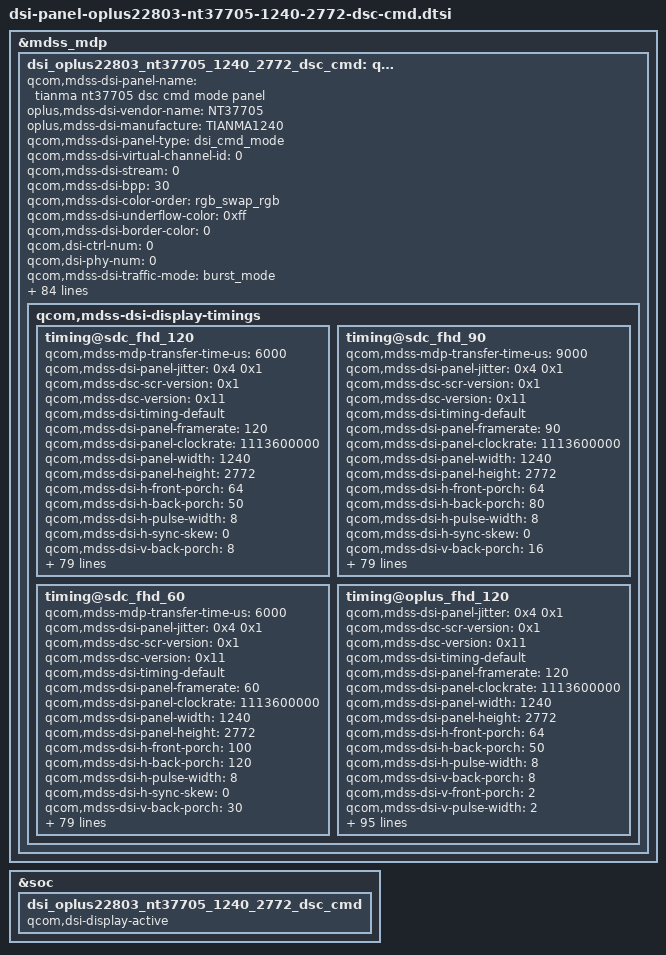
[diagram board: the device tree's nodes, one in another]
&mdss_mdp {
	dsi_oplus22803_nt37705_1240_2772_dsc_cmd: qcom,mdss_dsi_oplus22803_nt37705_1240_2772_dsc_cmd {
		qcom,mdss-dsi-panel-name = "tianma nt37705 dsc cmd mode panel";
		oplus,mdss-dsi-vendor-name = "NT37705";
		oplus,mdss-dsi-manufacture = "TIANMA1240";
		qcom,mdss-dsi-panel-type = "dsi_cmd_mode";
		qcom,mdss-dsi-virtual-channel-id = <0>;
		qcom,mdss-dsi-stream = <0>;
		qcom,mdss-dsi-bpp = <30>;
		qcom,mdss-dsi-color-order = "rgb_swap_rgb";
		qcom,mdss-dsi-underflow-color = <0xff>;
		qcom,mdss-dsi-border-color = <0>;
		qcom,dsi-ctrl-num = <0>;
		qcom,dsi-phy-num = <0>;
		qcom,mdss-dsi-traffic-mode = "burst_mode";
		qcom,mdss-dsi-lane-map = "lane_map_0123";
		qcom,mdss-dsi-bllp-eof-power-mode;
		qcom,mdss-dsi-bllp-power-mode;
		qcom,mdss-dsi-lane-0-state;
		qcom,mdss-dsi-lane-1-state;
		qcom,mdss-dsi-lane-2-state;
		qcom,mdss-dsi-lane-3-state;
		qcom,mdss-dsi-dma-trigger = "trigger_sw";
		qcom,mdss-loading-effect;
		qcom,mdss-dsi-mdp-trigger = "none";
		qcom,mdss-dsi-reset-sequence = <1 2>, <0 5>, <1 10>;
		qcom,mdss-dsi-te-pin-select = <1>;
		qcom,mdss-dsi-te-dcs-command = <1>;
		qcom,mdss-pan-physical-width-dimension = <70>;
		qcom,mdss-pan-physical-height-dimension = <155>;
		qcom,mdss-dsi-init-delay-us = <1000>;
		qcom,mdss-dsi-te-check-enable;
		qcom,mdss-dsi-te-using-te-pin;
		qcom,mdss-dsi-lp11-init;
		qcom,mdss-dsi-wr-mem-start = <0x2c>;
		qcom,mdss-dsi-wr-mem-continue = <0x3c>;
		qcom,mdss-dsi-panel-jitter = <0x4 0x1>;
		qcom,mdss-dsc-scr-version = <0x1>;
		qcom,mdss-bl-high2bit;
		/* HDR Setting */
		qcom,mdss-dsi-panel-hdr-enabled;
		qcom,mdss-dsi-panel-hdr-color-primaries = <15635 16450 34000 16000 13250 34500 7500 3000>;
		qcom,mdss-dsi-panel-peak-brightness = <5400000>;
		qcom,mdss-dsi-panel-average-brightness = <2000000>;
		qcom,mdss-dsi-panel-blackness-level = <4000>;

		qcom,esd-check-enabled;
		//oplus,esd-check-flag-enabled;
		qcom,mdss-dsi-panel-status-check-mode = "reg_read";
		qcom,mdss-dsi-panel-status-command = [
				06 01 00 01 05 00 02 0A 00
			];
		qcom,mdss-dsi-panel-status-command-state = "dsi_lp_mode";
		qcom,mdss-dsi-panel-status-value = <0x9C>;
		qcom,mdss-dsi-panel-status-read-length = <1>;

		qcom,dynamic-mode-switch-enabled;
		qcom,dynamic-mode-switch-type = "dynamic-resolution-switch-immediate";
		qcom,mdss-dsi-display-timings {
			timing@sdc_fhd_120{
				qcom,mdss-mdp-transfer-time-us = <6000>;
				qcom,mdss-dsi-panel-jitter = <0x4 0x1>;
				qcom,mdss-dsc-scr-version = <0x1>;
				qcom,mdss-dsc-version = <0x11>;
				qcom,mdss-dsi-timing-default;
				qcom,mdss-dsi-panel-framerate = <120>;
				qcom,mdss-dsi-panel-clockrate = <1113600000>;
				qcom,mdss-dsi-panel-width = <1240>;
				qcom,mdss-dsi-panel-height = <2772>;

				qcom,mdss-dsi-h-front-porch = <64>;
				qcom,mdss-dsi-h-back-porch = <50>;
				qcom,mdss-dsi-h-pulse-width = <8>;
				qcom,mdss-dsi-h-sync-skew = <0>;
				qcom,mdss-dsi-v-back-porch = <8>;
				qcom,mdss-dsi-v-front-porch = <2>;
				qcom,mdss-dsi-v-pulse-width = <2>;
				qcom,mdss-dsi-h-sync-pulse = <0>;

				qcom,mdss-dsi-h-left-border = <0>;
				qcom,mdss-dsi-h-right-border = <0>;
				qcom,mdss-dsi-v-top-border = <0>;
				qcom,mdss-dsi-v-bottom-border = <0>;

				/* Apollo vsync config, need to measure TE signal */
				//oplus,apollo-panel-vsync-width = <13000>;
				//oplus,apollo-panel-vsync-period = <16600>;

				oplus,fod-on-vblank = <0>;
				oplus,fod-off-vblank = <0>;
				qcom,mdss-dsi-panel-read-register-open-command = [
					39 01 00 00 00 00 03 F0 5A 5A
					];
				qcom,mdss-dsi-panel-id1-command = [
					06 01 00 00 00 00 01 E9
					];
				qcom,mdss-dsi-panel-read-register-close-command = [
					39 01 00 00 00 00 03 F0 A5 A5
					];
				qcom,mdss-dsi-timing-switch-command = [
					/* Frequence Transition */
					39 00 00 00 11 00 02 2F 00
					/* TE change */
					39 00 00 40 00 00 06 F0 55 AA 52 08 00
					39 00 00 00 00 00 02 BE 47

					39 00 00 40 00 00 06 F0 55 AA 52 08 00
					39 00 00 40 00 00 02 6F A8
					39 00 00 40 00 00 03 BA 00 00
					39 00 00 40 00 00 02 6F B0
					39 00 00 40 00 00 05 BA 00 00 00 00
					39 00 00 40 00 00 02 2F 30
					39 00 00 40 00 00 02 6D 00
					39 00 00 40 00 00 05 35 00 00 00 00
					39 00 00 00 00 00 03 44 00 00
					];
				qcom,mdss-dsi-on-command=[
					39 00 00 40 00 00 06 F0 55 AA 52 08 01
					39 00 00 40 00 00 02 6F 0C
					39 00 00 00 00 00 03 B5 80 E6
					39 00 00 40 00 00 05 FF AA 55 A5 81
					39 00 00 40 00 00 02 6F 19
					39 00 00 40 00 00 02 FB 00
					39 00 00 40 00 00 02 6F 05
					39 00 00 40 00 00 02 FE 34
					39 00 00 40 00 00 05 FF AA 55 A5 80
					39 00 00 40 00 00 02 6F 1A
					39 00 00 40 00 00 02 F4 55
					39 00 00 40 00 00 05 FF AA 55 A5 83
					39 00 00 40 00 00 02 6F 12
					39 00 00 40 00 00 02 FE 41
					39 00 00 40 00 00 02 5F 00
					39 00 00 40 00 00 02 26 00
					39 00 00 40 00 00 02 26 00
					39 00 00 40 00 00 02 17 10
					39 00 00 40 00 00 05 2A 00 00 04 D7
					39 00 00 00 00 00 05 2B 00 00 0A D3
					/*TE 120hz*/
					39 00 00 00 00 00 02 2F 00
					/*TE on*/
					39 00 00 40 00 00 02 35 00
					39 00 00 40 00 00 03 44 00 00
					/* Dimming Setting */
					39 00 00 40 00 00 03 51 0D BB
					39 00 00 00 00 00 02 6F 04
					39 00 00 40 00 00 03 51 03 FF
					39 00 00 00 00 00 02 53 20
					/*10bit DSC*/
					39 00 00 40 00 00 03 90 03 03
					39 00 00 00 00 00 13 91 AB 28 00 0C F2 00 02 85 01 0F 00 08 0A E9 07 5F 10 F0
					39 00 00 40 00 00 05 FF AA 55 A5 81
					39 00 00 40 00 00 02 6F 24
					39 00 00 40 00 00 15 FB 00 03 04 55 77 77 77 99 9D 00 00 06 88 9A BB BC DE EF F0 11
					39 00 00 40 00 00 05 FF AA 55 A5 81
					39 00 00 40 00 00 02 6F 0E
					39 00 00 40 00 00 02 F5 00
					39 00 00 40 00 00 05 FF AA 55 A5 80
					39 00 00 40 00 00 02 6F 0F
					39 00 00 40 00 00 02 FC 00
					39 00 00 40 00 00 02 6F 09
					39 00 00 00 00 00 03 FC FC F0
					/*OSC start*/
					39 00 00 40 00 00 05 FF AA 55 A5 80
					39 00 00 40 00 00 02 6F 0A
					39 00 00 40 00 00 04 F6 70 70 70
					39 00 00 40 00 00 02 6F 0E
					39 00 00 40 00 00 02 F6 60
					39 00 00 40 00 00 05 FF AA 55 A5 80
					39 00 00 40 00 00 02 6F 11
					39 00 00 40 00 00 03 F8 01 50
					39 00 00 40 00 00 02 6F 2D
					39 00 00 40 00 00 03 F8 00 FC
					39 00 00 40 00 00 02 6F 01
					39 00 00 40 00 00 02 1F 06
					39 00 00 40 00 00 05 FF AA 55 A5 81
					39 00 00 40 00 00 02 6F 1E
					39 00 00 00 00 00 02 FB 0F
					/*OSC end*/
					39 00 00 40 00 00 05 FF AA 55 A5 83
					39 00 00 40 00 00 02 6F 12
					39 00 00 40 00 00 02 FE 41
					39 00 00 40 00 00 05 FF AA 55 A5 80
					39 00 00 40 00 00 02 6F 19
					39 00 00 40 00 00 02 F2 00
					39 00 00 40 00 00 05 FF AA 55 A5 81
					39 00 00 40 00 00 02 6F 02
					39 00 00 40 00 00 02 F9 04
					39 00 00 00 00 00 02 5A 00
					39 00 00 40 00 00 06 F0 55 AA 52 08 01
					39 00 00 00 00 00 05 E9 58 08 08 28
					/* Switch to 120Hz */
					39 00 00 40 00 00 06 F0 55 AA 52 08 00
					39 00 00 40 00 00 02 6F A8
					39 00 00 40 00 00 03 BA 00 00
					39 00 00 40 00 00 02 6F B0
					39 00 00 40 00 00 05 BA 00 00 00 00
					39 00 00 40 00 00 02 2F 30
					39 00 00 40 00 00 02 6D 00
					39 00 00 40 00 00 05 35 00 00 00 00
					/* Edge Optimization Control */
					39 00 00 40 00 00 06 F0 55 AA 52 08 07
					39 00 00 00 00 00 0E B4 C0 80 80 80 80 50 80 80 80 80 80 50 80
					/* SPR Control */
					39 00 00 40 00 00 06 F0 55 AA 52 08 07
					39 00 00 00 00 00 07 B1 08 18 00 18 08 00
					/* R Corner Control */
					39 00 00 40 00 00 06 F0 55 AA 52 08 07
					39 00 00 40 00 00 04 C0 87 01 08
					39 00 00 40 00 00 02 6F 03
					39 00 00 40 00 00 0F C0 00 00 00 55 00 00 00 00 00 00 00 00 00 00
					39 00 00 40 00 00 02 6F 00
					39 00 00 40 00 00 16 C1 38 0F 0B 64 01 21 F8 D4 3F FC 8B 78 3F FF 19 B4 80 00 2E C8 91
					39 00 00 40 00 00 02 6F 15
					39 00 00 40 00 00 11 C1 66 00 00 11 00 39 A0 43 F0 9A EF 06 C6 C0 00 FF
					39 00 00 40 00 00 02 6F 25
					39 00 00 00 00 00 11 C1 00 2F 3A 00 07 0F 00 00 00 66 40 40 40 40 40 40
					39 00 00 40 00 00 02 6F 00
					39 00 00 40 00 00 16 C2 30 0F 01 00 05 10 FB 80 3F FF 48 00 3F FD 9E 00 00 00 21 C9 00
					39 00 00 40 00 00 02 6F 15
					39 00 00 40 00 00 11 C2 10 00 3B 98 00 00 10 34 F0 F0 A4 05 C0 30 FF 00
					39 00 00 40 00 00 02 6F 25
					39 00 00 00 00 00 11 C2 00 00 10 00 26 38 00 00 00 10 40 40 40 40 40 40
					39 00 00 40 00 00 02 6F 00
					39 00 00 40 00 00 16 C3 30 0F 00 79 00 90 FE F8 3F FF 76 E0 3F FF 70 D0 80 00 13 91 11
					39 00 00 40 00 00 02 6F 15
					39 00 00 40 00 00 11 C3 11 00 11 3A 00 10 38 44 F0 D9 D8 06 18 F0 FF FF
					39 00 00 40 00 00 02 6F 25
					39 00 00 00 00 00 11 C3 44 9D A3 00 08 0F 00 00 00 11 40 40 40 40 40 40
					39 00 00 40 00 00 02 6F 00
					39 00 00 40 00 00 16 C4 32 0F 01 21 06 40 FA B0 00 00 5A 50 00 04 66 84 FF FF AE 22 FC
					39 00 00 40 00 00 02 6F 15
					39 00 00 40 00 00 11 C4 11 44 34 9B AA C2 D3 34 0F 11 66 F9 3A 00 00 00
					39 00 00 40 00 00 02 6F 25
					39 00 00 00 00 00 11 C4 44 C7 D4 00 2C 39 00 00 00 11 40 40 40 40 40 40
					39 00 00 40 00 00 02 6F 00
					39 00 00 40 00 00 16 C5 3A 0F 00 79 00 90 FE F8 00 00 8B 88 00 00 8C 90 FF FF E7 3E 80
					39 00 00 40 00 00 02 6F 15
					39 00 00 40 00 00 11 C5 0D 44 9C C5 AA 9A C2 54 0F 27 28 F9 E8 00 00 00
					39 00 00 40 00 00 02 6F 25
					39 00 00 00 00 00 11 C5 44 C5 CC AA 9A A4 00 00 00 0D 40 40 40 40 40 40
					39 00 00 40 00 00 02 6F 00
					39 00 00 40 00 00 16 C6 3A 0F 07 90 01 44 F9 D0 00 05 1D C8 00 00 6F 60 7F FF 9A 55 B0
					39 00 00 40 00 00 02 6F 15
					39 00 00 40 00 00 11 C6 6A 44 C5 D7 AA 2E 99 43 0F 6A 12 F8 8C 00 00 00
					39 00 00 40 00 00 02 6F 25
					39 00 00 00 00 00 11 C6 44 9C A6 AA C2 CB 00 00 00 6A 40 40 40 40 40 40
					39 00 00 40 00 00 02 6F 00
					39 00 00 40 00 00 16 C7 36 00 01 00 05 10 04 80 00 00 00 00 3F FC 00 00 00 00 00 00 00
					39 00 00 40 00 00 02 6F 15
					39 00 00 40 00 00 11 C7 10 44 3F 9C 00 00 10 34 30 10 A4 00 00 00 00 00
					39 00 00 40 00 00 02 6F 25
					39 00 00 00 00 00 11 C7 00 09 12 AA 9A A4 00 00 00 10 40 40 40 40 40 40
					39 00 00 40 00 00 02 6F 00
					39 00 00 40 00 00 16 C8 36 00 00 79 00 90 01 08 00 00 63 50 3F FF 47 90 80 00 00 B9 00
					39 00 00 40 00 00 02 6F 15
					39 00 00 40 00 00 11 C8 11 44 9D C6 00 10 38 44 30 27 D8 00 00 C0 00 FF
					39 00 00 40 00 00 02 6F 25
					39 00 00 00 00 00 11 C8 00 31 3B AA C2 CD 00 00 00 11 40 40 40 40 40 40
					39 00 00 40 00 00 02 6F 00
					39 00 00 40 00 00 16 C9 2E 00 0B 64 01 21 07 2C 00 01 F1 40 3F FE 9F C8 80 00 01 61 59
					39 00 00 40 00 00 02 6F 15
					39 00 00 40 00 00 11 C9 66 44 C6 D7 00 39 A0 43 30 66 EF 00 00 C0 00 FF
					39 00 00 40 00 00 02 6F 25
					39 00 00 00 00 00 11 C9 00 00 00 00 00 00 00 00 00 66 40 40 40 40 40 40
					39 00 00 40 00 00 02 6F 00
					39 00 00 40 00 00 16 CA 2C 00 07 90 01 44 06 30 3F F9 D1 F8 00 00 00 00 00 00 00 00 00
					39 00 00 40 00 00 02 6F 15
					39 00 00 40 00 00 11 CA 6A 00 00 12 AA 2E 99 43 C0 96 12 00 00 00 00 00
					39 00 00 40 00 00 02 6F 25
					39 00 00 00 00 00 11 CA 00 00 00 00 00 00 00 00 00 6A 40 40 40 40 40 40
					39 00 00 40 00 00 02 6F 00
					39 00 00 40 00 00 16 CB 2C 00 00 79 00 90 01 08 3F FF 4E A8 00 00 63 50 00 00 00 B1 D1
					39 00 00 40 00 00 02 6F 15
					39 00 00 40 00 00 11 CB 0D 00 12 3B AA 9A C2 54 C0 D9 28 00 00 30 FF 00
					39 00 00 40 00 00 02 6F 25
					39 00 00 00 00 00 11 CB 00 00 00 00 00 00 00 00 00 0D 40 40 40 40 40 40
					39 00 00 40 00 00 02 6F 00
					39 00 00 40 00 00 16 CC 24 00 01 21 06 40 05 50 3F FE BF 64 00 02 48 A4 80 00 01 41 BD
					39 00 00 40 00 00 02 6F 15
					39 00 00 40 00 00 11 CC 11 00 3C A3 AA C2 D3 34 C0 EF 66 00 00 30 FF 00
					39 00 00 40 00 00 02 6F 25
					39 00 00 00 00 00 11 CC 00 00 00 00 00 00 00 00 00 11 40 40 40 40 40 40
					39 00 00 40 00 00 02 6F 00
					39 00 00 40 00 00 16 D1 21 00 04 C9 04 C9 00 00 3F FE B1 0A 3F FE B1 0A 00 00 19 8D 4F
					39 00 00 40 00 00 02 6F 15
					39 00 00 40 00 00 11 D1 0A 22 47 6B 00 25 49 55 F0 DD DD 04 C9 F0 FF FF
					39 00 00 40 00 00 02 6F 25
					39 00 00 00 00 00 11 D1 00 00 00 00 00 00 00 00 00 0A 40 40 40 40 40 40
					39 00 00 40 00 00 02 6F 00
					39 00 00 40 00 00 16 D2 27 00 04 C9 04 C9 00 00 00 00 00 00 3F FE B1 0A 00 00 01 53 BF
					39 00 00 40 00 00 02 6F 15
					39 00 00 40 00 00 11 D2 0A 22 6C 90 00 25 49 55 30 23 DD 00 00 C0 00 FF
					39 00 00 40 00 00 02 6F 25
					39 00 00 00 00 00 11 D2 00 00 00 00 00 00 00 00 00 0A 40 40 40 40 40 40
					39 00 00 40 00 00 02 6F 00
					39 00 00 40 00 00 16 D3 2D 00 04 C9 05 10 00 00 3F FE A7 78 00 00 00 00 00 00 01 5D 51
					39 00 00 40 00 00 02 6F 15
					39 00 00 40 00 00 11 D3 18 22 47 6C 00 4A 6E 55 C0 DD 24 00 00 30 FF 00
					39 00 00 40 00 00 02 6F 25
					39 00 00 00 00 00 11 D3 00 00 00 00 00 00 00 00 00 18 40 40 40 40 40 40
					39 00 00 40 00 00 02 6F 00
					39 00 00 40 00 00 16 D4 2B 00 04 C9 04 84 00 00 00 00 00 00 00 00 00 00 7F FF EA 64 5C
					39 00 00 40 00 00 02 6F 15
					39 00 00 40 00 00 11 D4 19 22 6D 90 00 4A 6E 55 0F 23 22 FB 5A 00 00 00
					39 00 00 40 00 00 02 6F 25
					39 00 00 00 00 00 11 D4 00 00 00 00 00 00 00 00 00 19 40 40 40 40 40 40
					/* corsstalk improvements */
					39 00 00 40 00 00 06 F0 55 AA 52 08 08
					39 00 00 40 00 00 03 BF 11 11
					39 00 00 40 00 00 02 6F 01
					39 00 00 40 00 00 02 BF 00
					39 00 00 40 00 00 02 6F 02
					39 00 00 40 00 00 02 BF 08
					39 00 00 40 00 00 02 6F 03
					39 00 00 40 00 00 0A BF 00 20 3F 59 73 A0 C0 E0 F0
					39 00 00 40 00 00 02 6F 0C
					39 00 00 40 00 00 09 BF 08 08 10 08 08 08 08 08
					39 00 00 40 00 00 02 6F 14
					39 00 00 40 00 00 09 BF 08 08 10 08 08 08 08 08
					39 00 00 40 00 00 02 6F 1C
					39 00 00 40 00 00 09 BF 20 28 20 10 08 04 00 00
					39 00 00 40 00 00 02 6F 24
					39 00 00 40 00 00 09 BF 20 28 20 10 08 04 00 00
					39 00 00 40 00 00 02 6F 2C
					39 00 00 40 00 00 0C BF 40 40 40 40 40 40 40 40 40 40 40
					39 00 00 40 00 00 02 6F 37
					39 00 00 40 00 00 0C BF 40 40 40 40 40 40 40 40 40 40 40
					39 00 00 40 00 00 02 6F 42
					39 00 00 40 00 00 09 BF 00 00 00 00 00 00 00 00
					39 00 00 40 00 00 02 6F 4A
					39 00 00 40 00 00 09 BF 00 00 00 00 00 00 00 00
					39 00 00 40 00 00 02 6F 52
					39 00 00 40 00 00 05 BF 40 40 40 40
					39 00 00 40 00 00 02 6F 56
					39 00 00 40 00 00 04 BF 40 40 40
					39 00 00 40 00 00 02 6F 59
					39 00 00 40 00 00 03 BF 00 10
					39 00 00 40 00 00 02 6F 5B
					39 00 00 40 00 00 02 BF 28
					39 00 00 40 00 00 02 6F 5C
					39 00 00 00 00 00 0A BF C0 20 40 60 80 A0 C0 C0 FF
					/* AOD remove black frame */
					39 00 00 00 00 00 06 F0 55 AA 52 08 01
					39 00 00 00 00 00 06 D2 00 00 00 00 15
					15 00 00 00 00 00 02 6F 05
					39 00 00 00 00 00 04 D2 01 00 00
					15 00 00 00 00 00 02 6F 0E
					39 00 00 00 00 00 06 D2 02 00 10 05 88
					39 00 00 00 00 00 0B E4 80 00 00 00 00 00 00 00 00 33
					15 00 00 00 00 00 02 6F 0A
					39 00 00 00 00 00 07 E4 80 00 00 10 00 53
					/* AOD improvements */
					39 00 00 00 00 00 06 F0 55 AA 52 08 05
					15 00 00 00 00 00 02 6F 16
					39 00 00 00 00 00 08 EC 55 01 AA AA AA AA AA
					39 00 00 00 00 00 06 F0 55 AA 52 08 01
					15 00 00 00 00 00 02 6F 2B
					15 00 00 00 00 00 02 B9 A0
					15 00 00 00 00 00 02 6F 37
					39 00 00 00 00 00 0B B9 32 32 32 32 32 23 23 23 23 23
					15 00 00 00 00 00 02 E7 B2
					15 00 00 00 00 00 02 6F 01
					15 00 00 00 00 00 02 E7 26
					15 00 00 00 00 00 02 6F 02
					39 00 00 00 00 00 15 E7 00 00 00 00 00 00 00 00 00 00 00 00 00 00 00 04 04 04 04 04
					15 00 00 00 00 00 02 6F 16
					39 00 00 00 00 00 15 E7 08 08 08 08 08 04 04 04 04 04 04 04 04 04 04 04 04 04 04 04
					15 00 00 00 00 00 02 6F 2A
					39 00 00 00 00 00 15 E7 0C 0C 0C 0C 0C 08 08 08 08 08 08 08 08 08 08 08 08 08 08 08
					15 00 00 00 00 00 02 6F 3E
					39 00 00 00 00 00 15 E7 00 00 00 00 00 00 00 00 00 00 00 00 00 00 00 00 00 00 00 00
					/* AOD off splash */
					39 00 00 00 00 00 06 F0 55 AA 52 08 01
					15 00 00 00 00 00 02 6F 0E
					39 00 00 00 00 00 06 D2 02 00 10 05 82
					/*sleep out*/
					05 00 00 00 78 00 01 11
					/*display on*/
					05 00 00 00 00 00 01 29
				];

				qcom,mdss-dsi-panel-info-switch-page-command = [
					/*read panel info switch page 01*/
					39 00 00 00 00 00 06 F0 55 AA 52 08 01
				];
				qcom,mdss-dsi-default-switch-page-command = [
					/*switch default page*/
					39 00 00 00 00 00 06 F0 55 AA 52 08 00
				];
				qcom,mdss-dsi-qsync-on-commands = [
					/* SDC Auto On */
				];
				qcom,mdss-dsi-qsync-off-commands = [
					/* SDC Auto Off */
				];
				qcom,mdss-dsi-qsync-min-fps-0-command = [
					/* SDC Auto Off */
					15 00 00 40 00 00 02 2F 00
					15 00 00 40 00 00 02 2F 30
					15 00 00 00 00 00 02 6D 00
				];
				qcom,mdss-dsi-qsync-min-fps-1-command = [
					/* SDC Auto On */
				];

				qcom,mdss-dsi-post-on-backlight = [
					/* Display On */
					05 01 00 00 00 00 02 29 00
				];
				qcom,mdss-dsi-off-command=[
					//39 01 00 00 00 00 06 F0 55 AA 52 08 01
					//15 01 00 00 00 00 02 CE 0C
					05 01 00 00 0A 00 02 28 00
					05 01 00 00 78 00 02 10 00
				];
				qcom,mdss-dsi-lp1-command = [
					/* Panel OFF */
					05 00 00 00 09 00 01 28
					/* AOD Mode ON Setting */
					39 00 00 00 00 00 06 F0 55 AA 52 08 00
					15 00 00 00 00 00 02 6F 0C
					39 00 00 00 00 00 03 B5 50 4B
					15 00 00 00 00 00 02 2F 00
					05 00 00 00 1E 00 01 39
					15 00 00 00 00 00 02 65 01
					15 00 00 00 00 00 02 6F 04
					39 00 00 00 00 00 03 51 02 FF
				];
				qcom,mdss-dsi-nolp-command = [
					05 00 00 00 09 00 01 28
					39 00 00 00 00 00 06 F0 55 AA 52 08 00
					15 00 00 00 00 00 02 6F 0C
					39 00 00 00 00 00 03 B5 4F 4B
					15 00 00 00 00 00 02 65 00
					05 00 00 00 00 00 01 38
					39 00 00 00 00 00 03 51 00 00
					05 00 00 00 00 00 01 29
				];
				qcom,mdss-dsi-hbm-off-command = [
					39 00 00 00 00 00 03 51 0D BB
				];
				qcom,mdss-dsi-hbm-on-command = [
					39 00 00 00 00 00 03 51 0F 00
				];
				qcom,mdss-dsi-aod-high-mode-command = [
					/* AOD 50nit */
					15 00 00 00 00 00 02 6F 04
					39 00 00 00 00 00 03 51 02 FF
				];
				qcom,mdss-dsi-aod-low-mode-command = [
					/* AOD 10nit */
					15 00 00 00 00 00 02 6F 04
					39 00 00 00 00 00 03 51 01 FF
				];
				//qcom,mdss-dsi-esd-switch-page-command = [
				//	39 01 00 00 00 00 05 FF AA 55 A5 81
				//	15 01 00 00 00 00 02 6F 0F
				//];
				qcom,mdss-dsi-bl-3plus-command = [
					/*3plus 51Hey > 0x643*/
					39 01 00 00 00 00 06 F0 55 AA 52 08 00
					39 01 00 00 00 00 02 6F 11
					39 01 00 00 00 00 04 B2 02 03 42
				];
				qcom,mdss-dsi-bl-16plus-command = [
					/*16plus 51Hey <= 0x643*/
					39 01 00 00 00 00 06 F0 55 AA 52 08 00
					39 01 00 00 00 00 02 6F 11
					39 01 00 00 00 00 04 B2 0F 17 4E
				];
				qcom,mdss-dsi-timing-switch-command-state = "dsi_hs_mode";
				qcom,mdss-dsi-on-command-state = "dsi_lp_mode";
				qcom,mdss-dsi-off-command-state = "dsi_hs_mode";
				qcom,mdss-dsi-hbm-on-command-state = "dsi_lp_mode";
				qcom,mdss-dsi-hbm-off-command-state = "dsi_lp_mode";
				qcom,mdss-dsi-bl-16plus-command-state = "dsi_hs_mode";
				qcom,mdss-dsi-bl-3plus-command-state = "dsi_hs_mode";
				qcom,mdss-dsi-panel-info-switch-page-command-state = "dsi_lp_mode";
				qcom,mdss-dsi-default-switch-page-command-state = "dsi_lp_mode";

				qcom,lm-split = <620 620>;
				qcom,compression-mode = "dsc";
				qcom,mdss-dsc-encoders = <2>;
				qcom,mdss-dsc-slice-height = <12>;
				qcom,mdss-dsc-slice-width = <620>;
				qcom,mdss-dsc-slice-per-pkt = <2>;
				qcom,mdss-dsc-bit-per-component = <10>;
				qcom,mdss-dsc-bit-per-pixel = <8>;
				qcom,mdss-dsc-block-prediction-enable;
				qcom,mdss-dsi-panel-id1-command-state = "dsi_lp_mode";
			};
			timing@sdc_fhd_90{
				qcom,mdss-mdp-transfer-time-us = <9000>;
				qcom,mdss-dsi-panel-jitter = <0x4 0x1>;
				qcom,mdss-dsc-scr-version = <0x1>;
				qcom,mdss-dsc-version = <0x11>;
				qcom,mdss-dsi-timing-default;
				qcom,mdss-dsi-panel-framerate = <90>;
				qcom,mdss-dsi-panel-clockrate = <1113600000>;
				qcom,mdss-dsi-panel-width = <1240>;
				qcom,mdss-dsi-panel-height = <2772>;

				qcom,mdss-dsi-h-front-porch = <64>;
				qcom,mdss-dsi-h-back-porch = <80>;
				qcom,mdss-dsi-h-pulse-width = <8>;
				qcom,mdss-dsi-h-sync-skew = <0>;
				qcom,mdss-dsi-v-back-porch = <16>;
				qcom,mdss-dsi-v-front-porch = <10>;
				qcom,mdss-dsi-v-pulse-width = <2>;
				qcom,mdss-dsi-h-sync-pulse = <0>;

				qcom,mdss-dsi-h-left-border = <0>;
				qcom,mdss-dsi-h-right-border = <0>;
				qcom,mdss-dsi-v-top-border = <0>;
				qcom,mdss-dsi-v-bottom-border = <0>;

				/* Apollo vsync config, need to measure TE signal */
				//oplus,apollo-panel-vsync-width = <13000>;
				//oplus,apollo-panel-vsync-period = <16600>;

				oplus,fod-on-vblank = <0>;
				oplus,fod-off-vblank = <0>;
				qcom,mdss-dsi-panel-read-register-open-command = [
					39 01 00 00 00 00 03 F0 5A 5A
					];
				qcom,mdss-dsi-panel-id1-command = [
					06 01 00 00 00 00 01 E9
					];
				qcom,mdss-dsi-panel-read-register-close-command = [
					39 01 00 00 00 00 03 F0 A5 A5
					];
				qcom,mdss-dsi-timing-switch-command = [
					/* Frequence Transition */
					39 00 00 00 11 00 02 2F 01
					/* TE change */
					39 00 00 40 00 00 06 F0 55 AA 52 08 00
					39 00 00 00 00 00 02 BE 47

					39 00 00 40 00 00 06 F0 55 AA 52 08 00
					39 00 00 40 00 00 02 6F A8
					39 00 00 40 00 00 03 BA 11 11
					39 00 00 40 00 00 02 6F B0
					39 00 00 40 00 00 05 BA 11 11 00 00
					39 00 00 40 00 00 02 2F 30
					39 00 00 40 00 00 02 6D 00
					39 00 00 40 00 00 05 35 00 00 00 00
					39 00 00 00 00 00 03 44 00 00
					];
				qcom,mdss-dsi-on-command=[
					39 00 00 40 00 00 06 F0 55 AA 52 08 01
					39 00 00 40 00 00 02 6F 0C
					39 00 00 00 00 00 03 B5 80 E6
					39 00 00 40 00 00 05 FF AA 55 A5 81
					39 00 00 40 00 00 02 6F 19
					39 00 00 40 00 00 02 FB 00
					39 00 00 40 00 00 02 6F 05
					39 00 00 40 00 00 02 FE 34
					39 00 00 40 00 00 05 FF AA 55 A5 80
					39 00 00 40 00 00 02 6F 1A
					39 00 00 40 00 00 02 F4 55
					39 00 00 40 00 00 05 FF AA 55 A5 83
					39 00 00 40 00 00 02 6F 12
					39 00 00 40 00 00 02 FE 41
					39 00 00 40 00 00 02 5F 00
					39 00 00 40 00 00 02 26 00
					39 00 00 40 00 00 02 26 00
					39 00 00 40 00 00 02 17 10
					39 00 00 40 00 00 05 2A 00 00 04 D7
					39 00 00 00 00 00 05 2B 00 00 0A D3
					/*TE 90hz*/
					39 00 00 00 00 00 02 2F 01
					/*TE on*/
					39 00 00 40 00 00 02 35 00
					39 00 00 40 00 00 03 44 00 00
					/* Dimming Setting */
					39 00 00 40 00 00 03 51 0D BB
					39 00 00 00 00 00 02 6F 04
					39 00 00 40 00 00 03 51 03 FF
					39 00 00 00 00 00 02 53 20
					/*10bit DSC*/
					39 00 00 40 00 00 03 90 03 03
					39 00 00 00 00 00 13 91 AB 28 00 0C F2 00 02 85 01 0F 00 08 0A E9 07 5F 10 F0
					39 00 00 40 00 00 05 FF AA 55 A5 81
					39 00 00 40 00 00 02 6F 24
					39 00 00 40 00 00 15 FB 00 03 04 55 77 77 77 99 9D 00 00 06 88 9A BB BC DE EF F0 11
					39 00 00 40 00 00 05 FF AA 55 A5 81
					39 00 00 40 00 00 02 6F 0E
					39 00 00 40 00 00 02 F5 00
					39 00 00 40 00 00 05 FF AA 55 A5 80
					39 00 00 40 00 00 02 6F 0F
					39 00 00 40 00 00 02 FC 00
					39 00 00 40 00 00 02 6F 09
					39 00 00 00 00 00 03 FC FC F0
					/*OSC start*/
					39 00 00 40 00 00 05 FF AA 55 A5 80
					39 00 00 40 00 00 02 6F 0A
					39 00 00 40 00 00 04 F6 70 70 70
					39 00 00 40 00 00 02 6F 0E
					39 00 00 40 00 00 02 F6 60
					39 00 00 40 00 00 05 FF AA 55 A5 80
					39 00 00 40 00 00 02 6F 11
					39 00 00 40 00 00 03 F8 01 50
					39 00 00 40 00 00 02 6F 2D
					39 00 00 40 00 00 03 F8 00 FC
					39 00 00 40 00 00 02 6F 01
					39 00 00 40 00 00 02 1F 06
					39 00 00 40 00 00 05 FF AA 55 A5 81
					39 00 00 40 00 00 02 6F 1E
					39 00 00 00 00 00 02 FB 0F
					/*OSC end*/
					39 00 00 40 00 00 05 FF AA 55 A5 83
					39 00 00 40 00 00 02 6F 12
					39 00 00 40 00 00 02 FE 41
					39 00 00 40 00 00 05 FF AA 55 A5 80
					39 00 00 40 00 00 02 6F 19
					39 00 00 40 00 00 02 F2 00
					39 00 00 40 00 00 05 FF AA 55 A5 81
					39 00 00 40 00 00 02 6F 02
					39 00 00 40 00 00 02 F9 04
					39 00 00 00 00 00 02 5A 00
					39 00 00 40 00 00 06 F0 55 AA 52 08 01
					39 00 00 00 00 00 05 E9 58 08 08 28
					/* Switch to 90Hz */
					39 00 00 40 00 00 06 F0 55 AA 52 08 00
					39 00 00 40 00 00 02 6F A8
					39 00 00 40 00 00 03 BA 11 11
					39 00 00 40 00 00 02 6F B0
					39 00 00 40 00 00 05 BA 11 11 00 00
					39 00 00 40 00 00 02 2F 30
					39 00 00 40 00 00 02 6D 00
					39 00 00 40 00 00 05 35 00 00 00 00
					/* Edge Optimization Control */
					39 00 00 40 00 00 06 F0 55 AA 52 08 07
					39 00 00 00 00 00 0E B4 C0 80 80 80 80 50 80 80 80 80 80 50 80
					/* SPR Control */
					39 00 00 40 00 00 06 F0 55 AA 52 08 07
					39 00 00 00 00 00 07 B1 08 18 00 18 08 00
					/* R Corner Control */
					39 00 00 40 00 00 06 F0 55 AA 52 08 07
					39 00 00 40 00 00 04 C0 87 01 08
					39 00 00 40 00 00 02 6F 03
					39 00 00 40 00 00 0F C0 00 00 00 55 00 00 00 00 00 00 00 00 00 00
					39 00 00 40 00 00 02 6F 00
					39 00 00 40 00 00 16 C1 38 0F 0B 64 01 21 F8 D4 3F FC 8B 78 3F FF 19 B4 80 00 2E C8 91
					39 00 00 40 00 00 02 6F 15
					39 00 00 40 00 00 11 C1 66 00 00 11 00 39 A0 43 F0 9A EF 06 C6 C0 00 FF
					39 00 00 40 00 00 02 6F 25
					39 00 00 00 00 00 11 C1 00 2F 3A 00 07 0F 00 00 00 66 40 40 40 40 40 40
					39 00 00 40 00 00 02 6F 00
					39 00 00 40 00 00 16 C2 30 0F 01 00 05 10 FB 80 3F FF 48 00 3F FD 9E 00 00 00 21 C9 00
					39 00 00 40 00 00 02 6F 15
					39 00 00 40 00 00 11 C2 10 00 3B 98 00 00 10 34 F0 F0 A4 05 C0 30 FF 00
					39 00 00 40 00 00 02 6F 25
					39 00 00 00 00 00 11 C2 00 00 10 00 26 38 00 00 00 10 40 40 40 40 40 40
					39 00 00 40 00 00 02 6F 00
					39 00 00 40 00 00 16 C3 30 0F 00 79 00 90 FE F8 3F FF 76 E0 3F FF 70 D0 80 00 13 91 11
					39 00 00 40 00 00 02 6F 15
					39 00 00 40 00 00 11 C3 11 00 11 3A 00 10 38 44 F0 D9 D8 06 18 F0 FF FF
					39 00 00 40 00 00 02 6F 25
					39 00 00 00 00 00 11 C3 44 9D A3 00 08 0F 00 00 00 11 40 40 40 40 40 40
					39 00 00 40 00 00 02 6F 00
					39 00 00 40 00 00 16 C4 32 0F 01 21 06 40 FA B0 00 00 5A 50 00 04 66 84 FF FF AE 22 FC
					39 00 00 40 00 00 02 6F 15
					39 00 00 40 00 00 11 C4 11 44 34 9B AA C2 D3 34 0F 11 66 F9 3A 00 00 00
					39 00 00 40 00 00 02 6F 25
					39 00 00 00 00 00 11 C4 44 C7 D4 00 2C 39 00 00 00 11 40 40 40 40 40 40
					39 00 00 40 00 00 02 6F 00
					39 00 00 40 00 00 16 C5 3A 0F 00 79 00 90 FE F8 00 00 8B 88 00 00 8C 90 FF FF E7 3E 80
					39 00 00 40 00 00 02 6F 15
					39 00 00 40 00 00 11 C5 0D 44 9C C5 AA 9A C2 54 0F 27 28 F9 E8 00 00 00
					39 00 00 40 00 00 02 6F 25
					39 00 00 00 00 00 11 C5 44 C5 CC AA 9A A4 00 00 00 0D 40 40 40 40 40 40
					39 00 00 40 00 00 02 6F 00
					39 00 00 40 00 00 16 C6 3A 0F 07 90 01 44 F9 D0 00 05 1D C8 00 00 6F 60 7F FF 9A 55 B0
					39 00 00 40 00 00 02 6F 15
					39 00 00 40 00 00 11 C6 6A 44 C5 D7 AA 2E 99 43 0F 6A 12 F8 8C 00 00 00
					39 00 00 40 00 00 02 6F 25
					39 00 00 00 00 00 11 C6 44 9C A6 AA C2 CB 00 00 00 6A 40 40 40 40 40 40
					39 00 00 40 00 00 02 6F 00
					39 00 00 40 00 00 16 C7 36 00 01 00 05 10 04 80 00 00 00 00 3F FC 00 00 00 00 00 00 00
					39 00 00 40 00 00 02 6F 15
					39 00 00 40 00 00 11 C7 10 44 3F 9C 00 00 10 34 30 10 A4 00 00 00 00 00
					39 00 00 40 00 00 02 6F 25
					39 00 00 00 00 00 11 C7 00 09 12 AA 9A A4 00 00 00 10 40 40 40 40 40 40
					39 00 00 40 00 00 02 6F 00
					39 00 00 40 00 00 16 C8 36 00 00 79 00 90 01 08 00 00 63 50 3F FF 47 90 80 00 00 B9 00
					39 00 00 40 00 00 02 6F 15
					39 00 00 40 00 00 11 C8 11 44 9D C6 00 10 38 44 30 27 D8 00 00 C0 00 FF
					39 00 00 40 00 00 02 6F 25
					39 00 00 00 00 00 11 C8 00 31 3B AA C2 CD 00 00 00 11 40 40 40 40 40 40
					39 00 00 40 00 00 02 6F 00
					39 00 00 40 00 00 16 C9 2E 00 0B 64 01 21 07 2C 00 01 F1 40 3F FE 9F C8 80 00 01 61 59
					39 00 00 40 00 00 02 6F 15
					39 00 00 40 00 00 11 C9 66 44 C6 D7 00 39 A0 43 30 66 EF 00 00 C0 00 FF
					39 00 00 40 00 00 02 6F 25
					39 00 00 00 00 00 11 C9 00 00 00 00 00 00 00 00 00 66 40 40 40 40 40 40
					39 00 00 40 00 00 02 6F 00
					39 00 00 40 00 00 16 CA 2C 00 07 90 01 44 06 30 3F F9 D1 F8 00 00 00 00 00 00 00 00 00
					39 00 00 40 00 00 02 6F 15
					39 00 00 40 00 00 11 CA 6A 00 00 12 AA 2E 99 43 C0 96 12 00 00 00 00 00
					39 00 00 40 00 00 02 6F 25
					39 00 00 00 00 00 11 CA 00 00 00 00 00 00 00 00 00 6A 40 40 40 40 40 40
					39 00 00 40 00 00 02 6F 00
					39 00 00 40 00 00 16 CB 2C 00 00 79 00 90 01 08 3F FF 4E A8 00 00 63 50 00 00 00 B1 D1
					39 00 00 40 00 00 02 6F 15
					39 00 00 40 00 00 11 CB 0D 00 12 3B AA 9A C2 54 C0 D9 28 00 00 30 FF 00
					39 00 00 40 00 00 02 6F 25
					39 00 00 00 00 00 11 CB 00 00 00 00 00 00 00 00 00 0D 40 40 40 40 40 40
					39 00 00 40 00 00 02 6F 00
					39 00 00 40 00 00 16 CC 24 00 01 21 06 40 05 50 3F FE BF 64 00 02 48 A4 80 00 01 41 BD
					39 00 00 40 00 00 02 6F 15
					39 00 00 40 00 00 11 CC 11 00 3C A3 AA C2 D3 34 C0 EF 66 00 00 30 FF 00
					39 00 00 40 00 00 02 6F 25
					39 00 00 00 00 00 11 CC 00 00 00 00 00 00 00 00 00 11 40 40 40 40 40 40
					39 00 00 40 00 00 02 6F 00
					39 00 00 40 00 00 16 D1 21 00 04 C9 04 C9 00 00 3F FE B1 0A 3F FE B1 0A 00 00 19 8D 4F
					39 00 00 40 00 00 02 6F 15
					39 00 00 40 00 00 11 D1 0A 22 47 6B 00 25 49 55 F0 DD DD 04 C9 F0 FF FF
					39 00 00 40 00 00 02 6F 25
					39 00 00 00 00 00 11 D1 00 00 00 00 00 00 00 00 00 0A 40 40 40 40 40 40
					39 00 00 40 00 00 02 6F 00
					39 00 00 40 00 00 16 D2 27 00 04 C9 04 C9 00 00 00 00 00 00 3F FE B1 0A 00 00 01 53 BF
					39 00 00 40 00 00 02 6F 15
					39 00 00 40 00 00 11 D2 0A 22 6C 90 00 25 49 55 30 23 DD 00 00 C0 00 FF
					39 00 00 40 00 00 02 6F 25
					39 00 00 00 00 00 11 D2 00 00 00 00 00 00 00 00 00 0A 40 40 40 40 40 40
					39 00 00 40 00 00 02 6F 00
					39 00 00 40 00 00 16 D3 2D 00 04 C9 05 10 00 00 3F FE A7 78 00 00 00 00 00 00 01 5D 51
					39 00 00 40 00 00 02 6F 15
					39 00 00 40 00 00 11 D3 18 22 47 6C 00 4A 6E 55 C0 DD 24 00 00 30 FF 00
					39 00 00 40 00 00 02 6F 25
					39 00 00 00 00 00 11 D3 00 00 00 00 00 00 00 00 00 18 40 40 40 40 40 40
					39 00 00 40 00 00 02 6F 00
					39 00 00 40 00 00 16 D4 2B 00 04 C9 04 84 00 00 00 00 00 00 00 00 00 00 7F FF EA 64 5C
					39 00 00 40 00 00 02 6F 15
					39 00 00 40 00 00 11 D4 19 22 6D 90 00 4A 6E 55 0F 23 22 FB 5A 00 00 00
					39 00 00 40 00 00 02 6F 25
					39 00 00 00 00 00 11 D4 00 00 00 00 00 00 00 00 00 19 40 40 40 40 40 40
					/* corsstalk improvements */
					39 00 00 40 00 00 06 F0 55 AA 52 08 08
					39 00 00 40 00 00 03 BF 11 11
					39 00 00 40 00 00 02 6F 01
					39 00 00 40 00 00 02 BF 00
					39 00 00 40 00 00 02 6F 02
					39 00 00 40 00 00 02 BF 08
					39 00 00 40 00 00 02 6F 03
					39 00 00 40 00 00 0A BF 00 20 3F 59 73 A0 C0 E0 F0
					39 00 00 40 00 00 02 6F 0C
					39 00 00 40 00 00 09 BF 08 08 10 08 08 08 08 08
					39 00 00 40 00 00 02 6F 14
					39 00 00 40 00 00 09 BF 08 08 10 08 08 08 08 08
					39 00 00 40 00 00 02 6F 1C
					39 00 00 40 00 00 09 BF 20 28 20 10 08 04 00 00
					39 00 00 40 00 00 02 6F 24
					39 00 00 40 00 00 09 BF 20 28 20 10 08 04 00 00
					39 00 00 40 00 00 02 6F 2C
					39 00 00 40 00 00 0C BF 40 40 40 40 40 40 40 40 40 40 40
					39 00 00 40 00 00 02 6F 37
					39 00 00 40 00 00 0C BF 40 40 40 40 40 40 40 40 40 40 40
					39 00 00 40 00 00 02 6F 42
					39 00 00 40 00 00 09 BF 00 00 00 00 00 00 00 00
					39 00 00 40 00 00 02 6F 4A
					39 00 00 40 00 00 09 BF 00 00 00 00 00 00 00 00
					39 00 00 40 00 00 02 6F 52
					39 00 00 40 00 00 05 BF 40 40 40 40
					39 00 00 40 00 00 02 6F 56
					39 00 00 40 00 00 04 BF 40 40 40
					39 00 00 40 00 00 02 6F 59
					39 00 00 40 00 00 03 BF 00 10
					39 00 00 40 00 00 02 6F 5B
					39 00 00 40 00 00 02 BF 28
					39 00 00 40 00 00 02 6F 5C
					39 00 00 00 00 00 0A BF C0 20 40 60 80 A0 C0 C0 FF
					/* AOD remove black frame */
					39 00 00 00 00 00 06 F0 55 AA 52 08 01
					39 00 00 00 00 00 06 D2 00 00 00 00 15
					15 00 00 00 00 00 02 6F 05
					39 00 00 00 00 00 04 D2 01 00 00
					15 00 00 00 00 00 02 6F 0E
					39 00 00 00 00 00 06 D2 02 00 10 05 88
					39 00 00 00 00 00 0B E4 80 00 00 00 00 00 00 00 00 33
					15 00 00 00 00 00 02 6F 0A
					39 00 00 00 00 00 07 E4 80 00 00 10 00 53
					/* AOD improvements */
					39 00 00 00 00 00 06 F0 55 AA 52 08 05
					15 00 00 00 00 00 02 6F 16
					39 00 00 00 00 00 08 EC 55 01 AA AA AA AA AA
					39 00 00 00 00 00 06 F0 55 AA 52 08 01
					15 00 00 00 00 00 02 6F 2B
					15 00 00 00 00 00 02 B9 A0
					15 00 00 00 00 00 02 6F 37
					39 00 00 00 00 00 0B B9 32 32 32 32 32 23 23 23 23 23
					15 00 00 00 00 00 02 E7 B2
					15 00 00 00 00 00 02 6F 01
					15 00 00 00 00 00 02 E7 26
					15 00 00 00 00 00 02 6F 02
					39 00 00 00 00 00 15 E7 00 00 00 00 00 00 00 00 00 00 00 00 00 00 00 04 04 04 04 04
					15 00 00 00 00 00 02 6F 16
					39 00 00 00 00 00 15 E7 08 08 08 08 08 04 04 04 04 04 04 04 04 04 04 04 04 04 04 04
					15 00 00 00 00 00 02 6F 2A
					39 00 00 00 00 00 15 E7 0C 0C 0C 0C 0C 08 08 08 08 08 08 08 08 08 08 08 08 08 08 08
					15 00 00 00 00 00 02 6F 3E
					39 00 00 00 00 00 15 E7 00 00 00 00 00 00 00 00 00 00 00 00 00 00 00 00 00 00 00 00
					/* AOD off splash */
					39 00 00 00 00 00 06 F0 55 AA 52 08 01
					15 00 00 00 00 00 02 6F 0E
					39 00 00 00 00 00 06 D2 02 00 10 05 82
					/*sleep out*/
					05 00 00 00 78 00 01 11
					/*display on*/
					05 00 00 00 00 00 01 29
				];

				qcom,mdss-dsi-panel-info-switch-page-command = [
					/*read panel info switch page 01*/
					39 00 00 00 00 00 06 F0 55 AA 52 08 01
				];
				qcom,mdss-dsi-default-switch-page-command = [
					/*switch default page*/
					39 00 00 00 00 00 06 F0 55 AA 52 08 00
				];
				qcom,mdss-dsi-qsync-on-commands = [
					/* SDC Auto On */
				];
				qcom,mdss-dsi-qsync-off-commands = [
					/* SDC Auto Off */
				];
				qcom,mdss-dsi-qsync-min-fps-0-command = [
					/* SDC Auto Off */
					15 00 00 40 00 00 02 2F 01
					15 00 00 40 00 00 02 2F 30
					15 00 00 00 00 00 02 6D 00
				];
				qcom,mdss-dsi-qsync-min-fps-1-command = [
					/* SDC Auto On */
				];

				qcom,mdss-dsi-post-on-backlight = [
					/* Display On */
					05 01 00 00 00 00 02 29 00
				];
				qcom,mdss-dsi-off-command=[
					//39 01 00 00 00 00 06 F0 55 AA 52 08 01
					//15 01 00 00 00 00 02 CE 0C
					05 01 00 00 0A 00 02 28 00
					05 01 00 00 78 00 02 10 00
				];
				qcom,mdss-dsi-lp1-command = [
					/* Panel OFF */
					05 00 00 00 0C 00 01 28
					/* AOD Mode ON Setting */
					39 00 00 00 00 00 06 F0 55 AA 52 08 00
					15 00 00 00 00 00 02 6F 0C
					39 00 00 00 00 00 03 B5 50 4B
					15 00 00 00 00 00 02 2F 00
					05 00 00 00 1E 00 01 39
					15 00 00 00 00 00 02 65 01
					15 00 00 00 00 00 02 6F 04
					39 00 00 00 00 00 03 51 02 FF
				];
				qcom,mdss-dsi-nolp-command = [
					05 00 00 00 0C 00 01 28
					39 00 00 00 00 00 06 F0 55 AA 52 08 00
					15 00 00 00 00 00 02 6F 0C
					39 00 00 00 00 00 03 B5 4F 4B
					15 00 00 00 00 00 02 65 00
					05 00 00 00 00 00 01 38
					39 00 00 00 00 00 03 51 00 00
					05 00 00 00 00 00 01 29
				];
				qcom,mdss-dsi-hbm-off-command = [
					39 00 00 00 00 00 03 51 0D BB
				];
				qcom,mdss-dsi-hbm-on-command = [
					39 00 00 00 00 00 03 51 0F 00
				];
				qcom,mdss-dsi-aod-high-mode-command = [
					/* AOD 50nit */
					15 00 00 00 00 00 02 6F 04
					39 00 00 00 00 00 03 51 02 FF
				];
				qcom,mdss-dsi-aod-low-mode-command = [
					/* AOD 10nit */
					15 00 00 00 00 00 02 6F 04
					39 00 00 00 00 00 03 51 01 FF
				];
				//qcom,mdss-dsi-esd-switch-page-command = [
				//	39 01 00 00 00 00 05 FF AA 55 A5 81
				//	15 01 00 00 00 00 02 6F 0F
				//];
				qcom,mdss-dsi-bl-3plus-command = [
					/*3plus 51Hey > 0x643*/
					39 01 00 00 00 00 06 F0 55 AA 52 08 00
					39 01 00 00 00 00 02 6F 11
					39 01 00 00 00 00 04 B2 02 03 42
				];
				qcom,mdss-dsi-bl-16plus-command = [
					/*16plus 51Hey <= 0x643*/
					39 01 00 00 00 00 06 F0 55 AA 52 08 00
					39 01 00 00 00 00 02 6F 11
					39 01 00 00 00 00 04 B2 0F 17 4E
				];
				qcom,mdss-dsi-timing-switch-command-state = "dsi_hs_mode";
				qcom,mdss-dsi-on-command-state = "dsi_lp_mode";
				qcom,mdss-dsi-off-command-state = "dsi_hs_mode";
				qcom,mdss-dsi-hbm-on-command-state = "dsi_lp_mode";
				qcom,mdss-dsi-hbm-off-command-state = "dsi_lp_mode";
				qcom,mdss-dsi-bl-16plus-command-state = "dsi_hs_mode";
				qcom,mdss-dsi-bl-3plus-command-state = "dsi_hs_mode";
				qcom,mdss-dsi-panel-info-switch-page-command-state = "dsi_lp_mode";
				qcom,mdss-dsi-default-switch-page-command-state = "dsi_lp_mode";

				qcom,lm-split = <620 620>;
				qcom,compression-mode = "dsc";
				qcom,mdss-dsc-encoders = <2>;
				qcom,mdss-dsc-slice-height = <12>;
				qcom,mdss-dsc-slice-width = <620>;
				qcom,mdss-dsc-slice-per-pkt = <2>;
				qcom,mdss-dsc-bit-per-component = <10>;
				qcom,mdss-dsc-bit-per-pixel = <8>;
				qcom,mdss-dsc-block-prediction-enable;
				qcom,mdss-dsi-panel-id1-command-state = "dsi_lp_mode";
			};
			timing@sdc_fhd_60{
				qcom,mdss-mdp-transfer-time-us = <6000>;
				qcom,mdss-dsi-panel-jitter = <0x4 0x1>;
				qcom,mdss-dsc-scr-version = <0x1>;
				qcom,mdss-dsc-version = <0x11>;
				qcom,mdss-dsi-timing-default;
				qcom,mdss-dsi-panel-framerate = <60>;
				qcom,mdss-dsi-panel-clockrate = <1113600000>;
				qcom,mdss-dsi-panel-width = <1240>;
				qcom,mdss-dsi-panel-height = <2772>;

				qcom,mdss-dsi-h-front-porch = <100>;
				qcom,mdss-dsi-h-back-porch = <120>;
				qcom,mdss-dsi-h-pulse-width = <8>;
				qcom,mdss-dsi-h-sync-skew = <0>;
				qcom,mdss-dsi-v-back-porch = <30>;
				qcom,mdss-dsi-v-front-porch = <20>;
				qcom,mdss-dsi-v-pulse-width = <2>;
				qcom,mdss-dsi-h-sync-pulse = <0>;

				qcom,mdss-dsi-h-left-border = <0>;
				qcom,mdss-dsi-h-right-border = <0>;
				qcom,mdss-dsi-v-top-border = <0>;
				qcom,mdss-dsi-v-bottom-border = <0>;

				/* Apollo vsync config, need to measure TE signal */
				//oplus,apollo-panel-vsync-width = <13000>;
				//oplus,apollo-panel-vsync-period = <16600>;

				oplus,fod-on-vblank = <0>;
				oplus,fod-off-vblank = <0>;
				qcom,mdss-dsi-panel-read-register-open-command = [
					39 01 00 00 00 00 03 F0 5A 5A
					];
				qcom,mdss-dsi-panel-id1-command = [
					06 01 00 00 00 00 01 E9
					];
				qcom,mdss-dsi-panel-read-register-close-command = [
					39 01 00 00 00 00 03 F0 A5 A5
					];
				qcom,mdss-dsi-timing-switch-command = [
					/* Frequence Transition */
					39 00 00 00 11 00 02 2F 00
					/* TE change */
					39 00 00 40 00 00 06 F0 55 AA 52 08 00
					39 00 00 00 00 00 02 BE 47

					39 00 00 40 00 00 06 F0 55 AA 52 08 00
					39 00 00 40 00 00 02 6F A8
					39 00 00 40 00 00 03 BA 00 00
					39 00 00 40 00 00 02 6F B0
					39 00 00 40 00 00 05 BA 00 00 00 00
					39 00 00 40 00 00 02 2F 30
					39 00 00 40 00 00 02 6D 01
					39 00 00 40 00 00 05 35 00 00 00 01
					39 00 00 00 00 00 03 44 08 DF
					];
				qcom,mdss-dsi-on-command=[
					39 00 00 40 00 00 06 F0 55 AA 52 08 01
					39 00 00 40 00 00 02 6F 0C
					39 00 00 00 00 00 03 B5 80 E6
					39 00 00 40 00 00 05 FF AA 55 A5 81
					39 00 00 40 00 00 02 6F 19
					39 00 00 40 00 00 02 FB 00
					39 00 00 40 00 00 02 6F 05
					39 00 00 40 00 00 02 FE 34
					39 00 00 40 00 00 05 FF AA 55 A5 80
					39 00 00 40 00 00 02 6F 1A
					39 00 00 40 00 00 02 F4 55
					39 00 00 40 00 00 05 FF AA 55 A5 83
					39 00 00 40 00 00 02 6F 12
					39 00 00 40 00 00 02 FE 41
					39 00 00 40 00 00 02 5F 00
					39 00 00 40 00 00 02 26 00
					39 00 00 40 00 00 02 26 00
					39 00 00 40 00 00 02 17 10
					39 00 00 40 00 00 05 2A 00 00 04 D7
					39 00 00 00 00 00 05 2B 00 00 0A D3
					/*TE 120hz*/
					39 00 00 00 00 00 02 2F 00
					/*TE on*/
					39 00 00 40 00 00 02 35 00
					39 00 00 00 00 00 03 44 00 00
					/*Dimming Setting*/
					39 00 00 40 00 00 03 51 0D BB
					39 00 00 40 00 00 02 6F 04
					39 00 00 40 00 00 03 51 03 FF
					39 00 00 00 00 00 02 53 20
					/*10bit DSC*/
					39 00 00 40 00 00 03 90 03 03
					39 00 00 00 00 00 13 91 AB 28 00 0C F2 00 02 85 01 0F 00 08 0A E9 07 5F 10 F0
					39 00 00 40 00 00 05 FF AA 55 A5 81
					39 00 00 40 00 00 02 6F 24
					39 00 00 40 00 00 15 FB 00 03 04 55 77 77 77 99 9D 00 00 06 88 9A BB BC DE EF F0 11
					39 00 00 40 00 00 05 FF AA 55 A5 81
					39 00 00 40 00 00 02 6F 0E
					39 00 00 40 00 00 02 F5 00
					39 00 00 40 00 00 05 FF AA 55 A5 80
					39 00 00 40 00 00 02 6F 0F
					39 00 00 40 00 00 02 FC 00
					39 00 00 40 00 00 02 6F 09
					39 00 00 00 00 00 03 FC FC F0
					/*OSC start*/
					39 00 00 40 00 00 05 FF AA 55 A5 80
					39 00 00 40 00 00 02 6F 0A
					39 00 00 40 00 00 04 F6 70 70 70
					39 00 00 40 00 00 02 6F 0E
					39 00 00 40 00 00 02 F6 60
					39 00 00 40 00 00 05 FF AA 55 A5 80
					39 00 00 40 00 00 02 6F 11
					39 00 00 40 00 00 03 F8 01 50
					39 00 00 40 00 00 02 6F 2D
					39 00 00 40 00 00 03 F8 00 FC
					39 00 00 40 00 00 02 6F 01
					39 00 00 40 00 00 02 1F 06
					39 00 00 40 00 00 05 FF AA 55 A5 81
					39 00 00 40 00 00 02 6F 1E
					39 00 00 00 00 00 02 FB 0F
					/*OSC end*/
					39 00 00 40 00 00 05 FF AA 55 A5 83
					39 00 00 40 00 00 02 6F 12
					39 00 00 40 00 00 02 FE 41
					39 00 00 40 00 00 05 FF AA 55 A5 80
					39 00 00 40 00 00 02 6F 19
					39 00 00 40 00 00 02 F2 00
					39 00 00 40 00 00 05 FF AA 55 A5 81
					39 00 00 40 00 00 02 6F 02
					39 00 00 40 00 00 02 F9 04
					39 00 00 00 00 00 02 5A 00
					39 00 00 40 00 00 06 F0 55 AA 52 08 01
					39 00 00 00 00 00 05 E9 58 08 08 28
					/* Switch to 60Hz */
					39 00 00 40 00 00 06 F0 55 AA 52 08 00
					39 00 00 40 00 00 02 6F A8
					39 00 00 40 00 00 03 BA 00 00
					39 00 00 40 00 00 02 6F B0
					39 00 00 40 00 00 05 BA 00 00 00 00
					39 00 00 40 00 00 02 2F 30
					39 00 00 40 00 00 02 6D 01
					39 00 00 40 00 00 05 35 00 00 00 01
					39 00 00 00 00 00 03 44 08 DF
					/* Edge Optimization Control */
					39 00 00 40 00 00 06 F0 55 AA 52 08 07
					39 00 00 00 00 00 0E B4 C0 80 80 80 80 50 80 80 80 80 80 50 80
					/* SPR Control */
					39 00 00 40 00 00 06 F0 55 AA 52 08 07
					39 00 00 00 00 00 07 B1 08 18 00 18 08 00
					/* R Corner Control */
					39 00 00 40 00 00 06 F0 55 AA 52 08 07
					39 00 00 40 00 00 04 C0 87 01 08
					39 00 00 40 00 00 02 6F 03
					39 00 00 40 00 00 0F C0 00 00 00 55 00 00 00 00 00 00 00 00 00 00
					39 00 00 40 00 00 02 6F 00
					39 00 00 40 00 00 16 C1 38 0F 0B 64 01 21 F8 D4 3F FC 8B 78 3F FF 19 B4 80 00 2E C8 91
					39 00 00 40 00 00 02 6F 15
					39 00 00 40 00 00 11 C1 66 00 00 11 00 39 A0 43 F0 9A EF 06 C6 C0 00 FF
					39 00 00 40 00 00 02 6F 25
					39 00 00 00 00 00 11 C1 00 2F 3A 00 07 0F 00 00 00 66 40 40 40 40 40 40
					39 00 00 40 00 00 02 6F 00
					39 00 00 40 00 00 16 C2 30 0F 01 00 05 10 FB 80 3F FF 48 00 3F FD 9E 00 00 00 21 C9 00
					39 00 00 40 00 00 02 6F 15
					39 00 00 40 00 00 11 C2 10 00 3B 98 00 00 10 34 F0 F0 A4 05 C0 30 FF 00
					39 00 00 40 00 00 02 6F 25
					39 00 00 00 00 00 11 C2 00 00 10 00 26 38 00 00 00 10 40 40 40 40 40 40
					39 00 00 40 00 00 02 6F 00
					39 00 00 40 00 00 16 C3 30 0F 00 79 00 90 FE F8 3F FF 76 E0 3F FF 70 D0 80 00 13 91 11
					39 00 00 40 00 00 02 6F 15
					39 00 00 40 00 00 11 C3 11 00 11 3A 00 10 38 44 F0 D9 D8 06 18 F0 FF FF
					39 00 00 40 00 00 02 6F 25
					39 00 00 00 00 00 11 C3 44 9D A3 00 08 0F 00 00 00 11 40 40 40 40 40 40
					39 00 00 40 00 00 02 6F 00
					39 00 00 40 00 00 16 C4 32 0F 01 21 06 40 FA B0 00 00 5A 50 00 04 66 84 FF FF AE 22 FC
					39 00 00 40 00 00 02 6F 15
					39 00 00 40 00 00 11 C4 11 44 34 9B AA C2 D3 34 0F 11 66 F9 3A 00 00 00
					39 00 00 40 00 00 02 6F 25
					39 00 00 00 00 00 11 C4 44 C7 D4 00 2C 39 00 00 00 11 40 40 40 40 40 40
					39 00 00 40 00 00 02 6F 00
					39 00 00 40 00 00 16 C5 3A 0F 00 79 00 90 FE F8 00 00 8B 88 00 00 8C 90 FF FF E7 3E 80
					39 00 00 40 00 00 02 6F 15
					39 00 00 40 00 00 11 C5 0D 44 9C C5 AA 9A C2 54 0F 27 28 F9 E8 00 00 00
					39 00 00 40 00 00 02 6F 25
					39 00 00 00 00 00 11 C5 44 C5 CC AA 9A A4 00 00 00 0D 40 40 40 40 40 40
					39 00 00 40 00 00 02 6F 00
					39 00 00 40 00 00 16 C6 3A 0F 07 90 01 44 F9 D0 00 05 1D C8 00 00 6F 60 7F FF 9A 55 B0
					39 00 00 40 00 00 02 6F 15
					39 00 00 40 00 00 11 C6 6A 44 C5 D7 AA 2E 99 43 0F 6A 12 F8 8C 00 00 00
					39 00 00 40 00 00 02 6F 25
					39 00 00 00 00 00 11 C6 44 9C A6 AA C2 CB 00 00 00 6A 40 40 40 40 40 40
					39 00 00 40 00 00 02 6F 00
					39 00 00 40 00 00 16 C7 36 00 01 00 05 10 04 80 00 00 00 00 3F FC 00 00 00 00 00 00 00
					39 00 00 40 00 00 02 6F 15
					39 00 00 40 00 00 11 C7 10 44 3F 9C 00 00 10 34 30 10 A4 00 00 00 00 00
					39 00 00 40 00 00 02 6F 25
					39 00 00 00 00 00 11 C7 00 09 12 AA 9A A4 00 00 00 10 40 40 40 40 40 40
					39 00 00 40 00 00 02 6F 00
					39 00 00 40 00 00 16 C8 36 00 00 79 00 90 01 08 00 00 63 50 3F FF 47 90 80 00 00 B9 00
					39 00 00 40 00 00 02 6F 15
					39 00 00 40 00 00 11 C8 11 44 9D C6 00 10 38 44 30 27 D8 00 00 C0 00 FF
					39 00 00 40 00 00 02 6F 25
					39 00 00 00 00 00 11 C8 00 31 3B AA C2 CD 00 00 00 11 40 40 40 40 40 40
					39 00 00 40 00 00 02 6F 00
					39 00 00 40 00 00 16 C9 2E 00 0B 64 01 21 07 2C 00 01 F1 40 3F FE 9F C8 80 00 01 61 59
					39 00 00 40 00 00 02 6F 15
					39 00 00 40 00 00 11 C9 66 44 C6 D7 00 39 A0 43 30 66 EF 00 00 C0 00 FF
					39 00 00 40 00 00 02 6F 25
					39 00 00 00 00 00 11 C9 00 00 00 00 00 00 00 00 00 66 40 40 40 40 40 40
					39 00 00 40 00 00 02 6F 00
					39 00 00 40 00 00 16 CA 2C 00 07 90 01 44 06 30 3F F9 D1 F8 00 00 00 00 00 00 00 00 00
					39 00 00 40 00 00 02 6F 15
					39 00 00 40 00 00 11 CA 6A 00 00 12 AA 2E 99 43 C0 96 12 00 00 00 00 00
					39 00 00 40 00 00 02 6F 25
					39 00 00 00 00 00 11 CA 00 00 00 00 00 00 00 00 00 6A 40 40 40 40 40 40
					39 00 00 40 00 00 02 6F 00
					39 00 00 40 00 00 16 CB 2C 00 00 79 00 90 01 08 3F FF 4E A8 00 00 63 50 00 00 00 B1 D1
					39 00 00 40 00 00 02 6F 15
					39 00 00 40 00 00 11 CB 0D 00 12 3B AA 9A C2 54 C0 D9 28 00 00 30 FF 00
					39 00 00 40 00 00 02 6F 25
					39 00 00 00 00 00 11 CB 00 00 00 00 00 00 00 00 00 0D 40 40 40 40 40 40
					39 00 00 40 00 00 02 6F 00
					39 00 00 40 00 00 16 CC 24 00 01 21 06 40 05 50 3F FE BF 64 00 02 48 A4 80 00 01 41 BD
					39 00 00 40 00 00 02 6F 15
					39 00 00 40 00 00 11 CC 11 00 3C A3 AA C2 D3 34 C0 EF 66 00 00 30 FF 00
					39 00 00 40 00 00 02 6F 25
					39 00 00 00 00 00 11 CC 00 00 00 00 00 00 00 00 00 11 40 40 40 40 40 40
					39 00 00 40 00 00 02 6F 00
					39 00 00 40 00 00 16 D1 21 00 04 C9 04 C9 00 00 3F FE B1 0A 3F FE B1 0A 00 00 19 8D 4F
					39 00 00 40 00 00 02 6F 15
					39 00 00 40 00 00 11 D1 0A 22 47 6B 00 25 49 55 F0 DD DD 04 C9 F0 FF FF
					39 00 00 40 00 00 02 6F 25
					39 00 00 00 00 00 11 D1 00 00 00 00 00 00 00 00 00 0A 40 40 40 40 40 40
					39 00 00 40 00 00 02 6F 00
					39 00 00 40 00 00 16 D2 27 00 04 C9 04 C9 00 00 00 00 00 00 3F FE B1 0A 00 00 01 53 BF
					39 00 00 40 00 00 02 6F 15
					39 00 00 40 00 00 11 D2 0A 22 6C 90 00 25 49 55 30 23 DD 00 00 C0 00 FF
					39 00 00 40 00 00 02 6F 25
					39 00 00 00 00 00 11 D2 00 00 00 00 00 00 00 00 00 0A 40 40 40 40 40 40
					39 00 00 40 00 00 02 6F 00
					39 00 00 40 00 00 16 D3 2D 00 04 C9 05 10 00 00 3F FE A7 78 00 00 00 00 00 00 01 5D 51
					39 00 00 40 00 00 02 6F 15
					39 00 00 40 00 00 11 D3 18 22 47 6C 00 4A 6E 55 C0 DD 24 00 00 30 FF 00
					39 00 00 40 00 00 02 6F 25
					39 00 00 00 00 00 11 D3 00 00 00 00 00 00 00 00 00 18 40 40 40 40 40 40
					39 00 00 40 00 00 02 6F 00
					39 00 00 40 00 00 16 D4 2B 00 04 C9 04 84 00 00 00 00 00 00 00 00 00 00 7F FF EA 64 5C
					39 00 00 40 00 00 02 6F 15
					39 00 00 40 00 00 11 D4 19 22 6D 90 00 4A 6E 55 0F 23 22 FB 5A 00 00 00
					39 00 00 40 00 00 02 6F 25
					39 00 00 00 00 00 11 D4 00 00 00 00 00 00 00 00 00 19 40 40 40 40 40 40
					/* corsstalk improvements */
					39 00 00 40 00 00 06 F0 55 AA 52 08 08
					39 00 00 40 00 00 03 BF 11 11
					39 00 00 40 00 00 02 6F 01
					39 00 00 40 00 00 02 BF 00
					39 00 00 40 00 00 02 6F 02
					39 00 00 40 00 00 02 BF 08
					39 00 00 40 00 00 02 6F 03
					39 00 00 40 00 00 0A BF 00 20 3F 59 73 A0 C0 E0 F0
					39 00 00 40 00 00 02 6F 0C
					39 00 00 40 00 00 09 BF 08 08 10 08 08 08 08 08
					39 00 00 40 00 00 02 6F 14
					39 00 00 40 00 00 09 BF 08 08 10 08 08 08 08 08
					39 00 00 40 00 00 02 6F 1C
					39 00 00 40 00 00 09 BF 20 28 20 10 08 04 00 00
					39 00 00 40 00 00 02 6F 24
					39 00 00 40 00 00 09 BF 20 28 20 10 08 04 00 00
					39 00 00 40 00 00 02 6F 2C
					39 00 00 40 00 00 0C BF 40 40 40 40 40 40 40 40 40 40 40
					39 00 00 40 00 00 02 6F 37
					39 00 00 40 00 00 0C BF 40 40 40 40 40 40 40 40 40 40 40
					39 00 00 40 00 00 02 6F 42
					39 00 00 40 00 00 09 BF 00 00 00 00 00 00 00 00
					39 00 00 40 00 00 02 6F 4A
					39 00 00 40 00 00 09 BF 00 00 00 00 00 00 00 00
					39 00 00 40 00 00 02 6F 52
					39 00 00 40 00 00 05 BF 40 40 40 40
					39 00 00 40 00 00 02 6F 56
					39 00 00 40 00 00 04 BF 40 40 40
					39 00 00 40 00 00 02 6F 59
					39 00 00 40 00 00 03 BF 00 10
					39 00 00 40 00 00 02 6F 5B
					39 00 00 40 00 00 02 BF 28
					39 00 00 40 00 00 02 6F 5C
					39 00 00 00 00 00 0A BF C0 20 40 60 80 A0 C0 C0 FF
					/* AOD remove black frame */
					39 00 00 00 00 00 06 F0 55 AA 52 08 01
					39 00 00 00 00 00 06 D2 00 00 00 00 15
					15 00 00 00 00 00 02 6F 05
					39 00 00 00 00 00 04 D2 01 00 00
					15 00 00 00 00 00 02 6F 0E
					39 00 00 00 00 00 06 D2 02 00 10 05 88
					39 00 00 00 00 00 0B E4 80 00 00 00 00 00 00 00 00 33
					15 00 00 00 00 00 02 6F 0A
					39 00 00 00 00 00 07 E4 80 00 00 10 00 53
					/* AOD improvements */
					39 00 00 00 00 00 06 F0 55 AA 52 08 05
					15 00 00 00 00 00 02 6F 16
					39 00 00 00 00 00 08 EC 55 01 AA AA AA AA AA
					39 00 00 00 00 00 06 F0 55 AA 52 08 01
					15 00 00 00 00 00 02 6F 2B
					15 00 00 00 00 00 02 B9 A0
					15 00 00 00 00 00 02 6F 37
					39 00 00 00 00 00 0B B9 32 32 32 32 32 23 23 23 23 23
					15 00 00 00 00 00 02 E7 B2
					15 00 00 00 00 00 02 6F 01
					15 00 00 00 00 00 02 E7 26
					15 00 00 00 00 00 02 6F 02
					39 00 00 00 00 00 15 E7 00 00 00 00 00 00 00 00 00 00 00 00 00 00 00 04 04 04 04 04
					15 00 00 00 00 00 02 6F 16
					39 00 00 00 00 00 15 E7 08 08 08 08 08 04 04 04 04 04 04 04 04 04 04 04 04 04 04 04
					15 00 00 00 00 00 02 6F 2A
					39 00 00 00 00 00 15 E7 0C 0C 0C 0C 0C 08 08 08 08 08 08 08 08 08 08 08 08 08 08 08
					15 00 00 00 00 00 02 6F 3E
					39 00 00 00 00 00 15 E7 00 00 00 00 00 00 00 00 00 00 00 00 00 00 00 00 00 00 00 00
					/* AOD off splash */
					39 00 00 00 00 00 06 F0 55 AA 52 08 01
					15 00 00 00 00 00 02 6F 0E
					39 00 00 00 00 00 06 D2 02 00 10 05 82
					/*sleep out*/
					05 00 00 00 78 00 01 11
					/*display on*/
					05 00 00 00 00 00 01 29
				];

				qcom,mdss-dsi-panel-info-switch-page-command = [
					/*read panel info switch page 01*/
					39 00 00 00 00 00 06 F0 55 AA 52 08 01
				];
				qcom,mdss-dsi-default-switch-page-command = [
					/*switch default page*/
					39 00 00 00 00 00 06 F0 55 AA 52 08 00
				];
				qcom,mdss-dsi-qsync-on-commands = [
					/* SDC Auto On */
				];
				qcom,mdss-dsi-qsync-off-commands = [
					/* SDC Auto Off */
				];
				qcom,mdss-dsi-qsync-min-fps-0-command = [
					/* SDC Auto Off */
					15 00 00 40 00 00 02 2F 00
					15 00 00 40 00 00 02 2F 30
					15 00 00 00 00 00 02 6D 00
				];
				qcom,mdss-dsi-qsync-min-fps-1-command = [
					/* SDC Auto On */
				];

				qcom,mdss-dsi-post-on-backlight = [
					/* Display On */
					05 01 00 00 00 00 02 29 00
				];
				qcom,mdss-dsi-off-command=[
					//39 01 00 00 00 00 06 F0 55 AA 52 08 01
					//15 01 00 00 00 00 02 CE 0C
					05 01 00 00 0A 00 02 28 00
					05 01 00 00 78 00 02 10 00
				];
				qcom,mdss-dsi-lp1-command = [
					/* Panel OFF */
					05 00 00 00 11 00 01 28
					/* AOD Mode ON Setting */
					39 00 00 00 00 00 06 F0 55 AA 52 08 00
					15 00 00 00 00 00 02 6F 0C
					39 00 00 00 00 00 03 B5 50 4B
					15 00 00 00 00 00 02 2F 00
					05 00 00 00 1E 00 01 39
					15 00 00 00 00 00 02 65 01
					15 00 00 00 00 00 02 6F 04
					39 00 00 00 00 00 03 51 02 FF
				];
				qcom,mdss-dsi-nolp-command = [
					05 00 00 00 11 00 01 28
					39 00 00 00 00 00 06 F0 55 AA 52 08 00
					15 00 00 00 00 00 02 6F 0C
					39 00 00 00 00 00 03 B5 4F 4B
					15 00 00 00 00 00 02 65 00
					05 00 00 00 00 00 01 38
					39 00 00 00 00 00 03 51 00 00
					05 00 00 00 00 00 01 29
				];
				qcom,mdss-dsi-hbm-off-command = [
					39 00 00 00 00 00 03 51 0D BB
				];
				qcom,mdss-dsi-hbm-on-command = [
					39 00 00 00 00 00 03 51 0F 00
				];
				qcom,mdss-dsi-aod-high-mode-command = [
					/* AOD 50nit */
					15 00 00 00 00 00 02 6F 04
					39 00 00 00 00 00 03 51 02 FF
				];
				qcom,mdss-dsi-aod-low-mode-command = [
					/* AOD 10nit */
					15 00 00 00 00 00 02 6F 04
					39 00 00 00 00 00 03 51 01 FF
				];
				//qcom,mdss-dsi-esd-switch-page-command = [
				//	39 01 00 00 00 00 05 FF AA 55 A5 81
				//	15 01 00 00 00 00 02 6F 0F
				//];
				qcom,mdss-dsi-bl-3plus-command = [
					/*3plus 51Hey > 0x643*/
					39 01 00 00 00 00 06 F0 55 AA 52 08 00
					39 01 00 00 00 00 02 6F 11
					39 01 00 00 00 00 04 B2 02 03 42
				];
				qcom,mdss-dsi-bl-16plus-command = [
					/*16plus 51Hey <= 0x643*/
					39 01 00 00 00 00 06 F0 55 AA 52 08 00
					39 01 00 00 00 00 02 6F 11
					39 01 00 00 00 00 04 B2 0F 17 4E
				];
				qcom,mdss-dsi-timing-switch-command-state = "dsi_hs_mode";
				qcom,mdss-dsi-on-command-state = "dsi_lp_mode";
				qcom,mdss-dsi-off-command-state = "dsi_hs_mode";
				qcom,mdss-dsi-hbm-on-command-state = "dsi_lp_mode";
				qcom,mdss-dsi-hbm-off-command-state = "dsi_lp_mode";
				qcom,mdss-dsi-bl-16plus-command-state = "dsi_hs_mode";
				qcom,mdss-dsi-bl-3plus-command-state = "dsi_hs_mode";
				qcom,mdss-dsi-panel-info-switch-page-command-state = "dsi_lp_mode";
				qcom,mdss-dsi-default-switch-page-command-state = "dsi_lp_mode";

				qcom,lm-split = <620 620>;
				qcom,compression-mode = "dsc";
				qcom,mdss-dsc-encoders = <2>;
				qcom,mdss-dsc-slice-height = <12>;
				qcom,mdss-dsc-slice-width = <620>;
				qcom,mdss-dsc-slice-per-pkt = <2>;
				qcom,mdss-dsc-bit-per-component = <10>;
				qcom,mdss-dsc-bit-per-pixel = <8>;
				qcom,mdss-dsc-block-prediction-enable;
				qcom,mdss-dsi-panel-id1-command-state = "dsi_lp_mode";
			};
			timing@oplus_fhd_120{
				//qcom,mdss-mdp-transfer-time-us = <12000>;
				qcom,mdss-dsi-panel-jitter = <0x4 0x1>;
				qcom,mdss-dsc-scr-version = <0x1>;
				qcom,mdss-dsc-version = <0x11>;
				qcom,mdss-dsi-timing-default;
				qcom,mdss-dsi-panel-framerate = <120>;
				qcom,mdss-dsi-panel-clockrate = <1113600000>;
				qcom,mdss-dsi-panel-width = <1240>;
				qcom,mdss-dsi-panel-height = <2772>;

				qcom,mdss-dsi-h-front-porch = <64>;
				qcom,mdss-dsi-h-back-porch = <50>;
				qcom,mdss-dsi-h-pulse-width = <8>;
				qcom,mdss-dsi-v-back-porch = <8>;
				qcom,mdss-dsi-v-front-porch = <2>;
				qcom,mdss-dsi-v-pulse-width = <2>;
				qcom,mdss-dsi-h-sync-pulse = <0>;

				qcom,mdss-dsi-h-left-border = <0>;
				qcom,mdss-dsi-h-right-border = <0>;
				qcom,mdss-dsi-v-top-border = <0>;
				qcom,mdss-dsi-v-bottom-border = <0>;

				/* OPLUS ADFR */
				qcom,mdss-dsi-h-sync-skew = <2>;
				qcom,mdss-dsi-qsync-min-fps-0 = <30>;
				qcom,mdss-dsi-qsync-min-fps-1 = <40>;
				qcom,mdss-dsi-qsync-min-fps-2 = <60>;

				/* Apollo vsync config, need to measure TE signal */
				//oplus,apollo-panel-vsync-width = <13000>;
				//oplus,apollo-panel-vsync-period = <16600>;

				oplus,fod-on-vblank = <0>;
				oplus,fod-off-vblank = <0>;
				qcom,mdss-dsi-panel-read-register-open-command = [
					39 01 00 00 00 00 03 F0 5A 5A
					];
				qcom,mdss-dsi-panel-id1-command = [
					06 01 00 00 00 00 01 E9
					];
				qcom,mdss-dsi-panel-read-register-close-command = [
					39 01 00 00 00 00 03 F0 A5 A5
					];
				qcom,mdss-dsi-timing-switch-command = [
					/* Frequence Transition */
					39 00 00 00 11 00 02 2F 00
					/* TE change */
					39 01 00 00 00 00 06 F0 55 AA 52 08 00
					39 01 00 00 00 00 02 BE 5F

					39 01 00 00 00 00 05 35 00 00 00 00
					15 01 00 00 00 00 02 2F 30
					15 00 00 40 00 00 02 6D 00

					39 01 00 00 00 00 06 F0 55 AA 52 08 00
					39 01 00 00 00 00 02 6F A8
					39 01 00 00 00 00 03 BA 00 00

					39 01 00 00 00 00 02 6F B0
					39 01 00 00 00 00 05 BA 00 00 00 00
					];
				qcom,mdss-dsi-on-command=[
					39 00 00 40 00 00 06 F0 55 AA 52 08 01
					39 00 00 40 00 00 02 6F 0C
					39 00 00 00 00 00 03 B5 80 E6
					39 00 00 40 00 00 05 FF AA 55 A5 81
					39 00 00 40 00 00 02 6F 19
					39 00 00 40 00 00 02 FB 00
					39 00 00 40 00 00 02 6F 05
					39 00 00 40 00 00 02 FE 34
					39 00 00 40 00 00 05 FF AA 55 A5 80
					39 00 00 40 00 00 02 6F 1A
					39 00 00 40 00 00 02 F4 55
					39 00 00 40 00 00 05 FF AA 55 A5 83
					39 00 00 40 00 00 02 6F 12
					39 00 00 40 00 00 02 FE 41
					39 00 00 40 00 00 02 5F 00
					39 00 00 40 00 00 02 26 00
					39 00 00 40 00 00 02 26 00
					39 00 00 40 00 00 02 17 10
					39 00 00 40 00 00 05 2A 00 00 04 D7
					39 00 00 00 00 00 05 2B 00 00 0A D3
					/*120hz*/
					39 00 00 00 00 00 02 2F 00
					/*TE on*/
					39 00 00 40 00 00 02 35 00
					39 00 00 40 00 00 03 44 00 00
					/*Dimming Setting + AOD 51*/
					39 00 00 40 00 00 03 51 0D BB
					39 00 00 00 00 00 02 6F 04
					39 00 00 40 00 00 03 51 03 FF
					39 00 00 00 00 00 02 53 20
					/*10bit DSC*/
					39 00 00 40 00 00 03 90 03 03
					39 00 00 00 00 00 13 91 AB 28 00 0C F2 00 02 85 01 0F 00 08 0A E9 07 5F 10 F0
					39 00 00 40 00 00 05 FF AA 55 A5 81
					39 00 00 40 00 00 02 6F 24
					39 00 00 40 00 00 15 FB 00 03 04 55 77 77 77 99 9D 00 00 06 88 9A BB BC DE EF F0 11
					39 00 00 40 00 00 05 FF AA 55 A5 81
					39 00 00 40 00 00 02 6F 0E
					39 00 00 40 00 00 02 F5 00
					39 00 00 40 00 00 05 FF AA 55 A5 80
					39 00 00 40 00 00 02 6F 0F
					39 00 00 40 00 00 02 FC 00
					39 00 00 40 00 00 02 6F 09
					39 00 00 00 00 00 03 FC FC F0
					/*OSC start*/
					39 00 00 40 00 00 05 FF AA 55 A5 80
					39 00 00 40 00 00 02 6F 0A
					39 00 00 40 00 00 04 F6 70 70 70
					39 00 00 40 00 00 02 6F 0E
					39 00 00 40 00 00 02 F6 60
					39 00 00 40 00 00 05 FF AA 55 A5 80
					39 00 00 40 00 00 02 6F 11
					39 00 00 40 00 00 03 F8 01 50
					39 00 00 40 00 00 02 6F 2D
					39 00 00 40 00 00 03 F8 00 FC
					39 00 00 40 00 00 02 6F 01
					39 00 00 40 00 00 02 1F 06
					39 00 00 40 00 00 05 FF AA 55 A5 81
					39 00 00 40 00 00 02 6F 1E
					39 00 00 00 00 00 02 FB 0F
					/*OSC end*/
					39 00 00 40 00 00 05 FF AA 55 A5 83
					39 00 00 40 00 00 02 6F 12
					39 00 00 40 00 00 02 FE 41
					39 00 00 40 00 00 05 FF AA 55 A5 80
					39 00 00 40 00 00 02 6F 19
					39 00 00 40 00 00 02 F2 00
					39 00 00 40 00 00 05 FF AA 55 A5 81
					39 00 00 40 00 00 02 6F 02
					39 00 00 40 00 00 02 F9 04
					39 00 00 00 00 00 02 5A 00
					/*sleep out*/
					05 00 00 00 78 00 01 11
					/*display on*/
					05 00 00 00 00 00 01 29
				];

				qcom,mdss-dsi-panel-info-switch-page-command = [
					/*read panel info switch page 01*/
					39 00 00 00 00 00 06 F0 55 AA 52 08 01
				];
				qcom,mdss-dsi-default-switch-page-command = [
					/*switch default page*/
					39 00 00 00 00 00 06 F0 55 AA 52 08 00
				];
				qcom,mdss-dsi-qsync-on-commands = [
				];
				qcom,mdss-dsi-qsync-off-commands = [
					15 00 00 40 00 00 02 2F 00
					15 00 00 40 00 00 02 2F 30
					15 00 00 00 00 00 02 6D 00
				];
				qcom,mdss-dsi-qsync-min-fps-0-command = [
					15 00 00 40 00 00 02 2F 00
					15 00 00 40 00 00 02 2F 30
					15 00 00 00 00 00 02 6D 03
				];
				qcom,mdss-dsi-qsync-min-fps-1-command = [
					15 00 00 40 00 00 02 2F 00
					15 00 00 40 00 00 02 2F 30
					15 00 00 00 00 00 02 6D 02
				];
				qcom,mdss-dsi-qsync-min-fps-2-command = [
					15 00 00 40 00 00 02 2F 00
					15 00 00 40 00 00 02 2F 30
					15 00 00 00 00 00 02 6D 01
				];

				qcom,mdss-dsi-post-on-backlight = [
					/* Display On */
					05 01 00 00 00 00 02 29 00
				];
				qcom,mdss-dsi-off-command=[
					//39 01 00 00 00 00 06 F0 55 AA 52 08 01
					//15 01 00 00 00 00 02 CE 0C
					05 01 00 00 0A 00 02 28 00
					05 01 00 00 78 00 02 10 00
				];
				qcom,mdss-dsi-lp1-command = [
					/* Panel OFF */
					05 00 00 00 09 01 28
					/* AOD Mode ON Setting */
					39 00 00 40 00 06 F0 55 AA 52 08 00
					15 00 00 40 00 02 6F 0C
					39 00 00 00 00 03 B5 50 4B
					15 00 00 00 00 02 2F 00
					05 00 00 00 1E 01 39
					15 00 00 00 00 02 65 01
					15 00 00 40 00 02 6F 04
					39 00 00 00 00 03 51 02 FF
				];
				qcom,mdss-dsi-nolp-command = [
					05 00 00 00 09 01 28
					39 00 00 40 00 06 F0 55 AA 52 08 00
					15 00 00 40 00 02 6F 0C
					39 00 00 40 00 03 B5 50 4B
					15 00 00 40 00 02 65 00
					05 00 00 40 00 01 38
					39 00 00 00 00 03 51 00 00
					05 00 00 00 00 01 29
				];
				qcom,mdss-dsi-hbm-off-command = [
					39 00 00 00 00 00 03 51 0D BB
				];
				qcom,mdss-dsi-hbm-on-command = [
					39 00 00 00 00 00 03 51 0F 00
				];
				qcom,mdss-dsi-aod-high-mode-command = [
					/* AOD 50nit */
					15 00 00 40 00 00 02 6F 04
					39 00 00 00 00 00 03 51 02 FF
				];
				qcom,mdss-dsi-aod-low-mode-command = [
					/* AOD 10nit */
					15 00 00 40 00 00 02 6F 04
					39 00 00 00 00 00 03 51 01 FF
				];
				//qcom,mdss-dsi-esd-switch-page-command = [
				//	39 01 00 00 00 00 05 FF AA 55 A5 81
				//	15 01 00 00 00 00 02 6F 0F
				//];
				qcom,mdss-dsi-bl-3plus-command = [
					/*3plus 51Hey > 0x643*/
					39 01 00 00 00 00 06 F0 55 AA 52 08 00
					39 01 00 00 00 00 02 6F 11
					39 01 00 00 00 00 04 B2 02 03 42
				];
				qcom,mdss-dsi-bl-16plus-command = [
					/*16plus 51Hey <= 0x643*/
					39 01 00 00 00 00 06 F0 55 AA 52 08 00
					39 01 00 00 00 00 02 6F 11
					39 01 00 00 00 00 04 B2 0F 17 4E
				];
				qcom,mdss-dsi-timing-switch-command-state = "dsi_hs_mode";
				qcom,mdss-dsi-on-command-state = "dsi_lp_mode";
				qcom,mdss-dsi-off-command-state = "dsi_hs_mode";
				qcom,mdss-dsi-qsync-on-commands-state ="dsi_hs_mode";
				qcom,mdss-dsi-qsync-off-commands-state ="dsi_hs_mode";
				qcom,mdss-dsi-qsync-min-fps-0-command-state = "dsi_hs_mode";
				qcom,mdss-dsi-qsync-min-fps-1-command-state = "dsi_hs_mode";
				qcom,mdss-dsi-qsync-min-fps-2-command-state = "dsi_hs_mode";
				qcom,mdss-dsi-hbm-on-command-state = "dsi_lp_mode";
				qcom,mdss-dsi-hbm-off-command-state = "dsi_lp_mode";
				qcom,mdss-dsi-bl-16plus-command-state = "dsi_hs_mode";
				qcom,mdss-dsi-bl-3plus-command-state = "dsi_hs_mode";
				qcom,mdss-dsi-panel-info-switch-page-command-state = "dsi_lp_mode";
				qcom,mdss-dsi-default-switch-page-command-state = "dsi_lp_mode";

				qcom,lm-split = <620 620>;
				qcom,compression-mode = "dsc";
				qcom,mdss-dsc-encoders = <2>;
				qcom,mdss-dsc-slice-height = <12>;
				qcom,mdss-dsc-slice-width = <620>;
				qcom,mdss-dsc-slice-per-pkt = <2>;
				qcom,mdss-dsc-bit-per-component = <10>;
				qcom,mdss-dsc-bit-per-pixel = <8>;
				qcom,mdss-dsc-block-prediction-enable;
				qcom,mdss-dsi-panel-id1-command-state = "dsi_lp_mode";
			};

		};
	};
};

&soc {
	dsi_oplus22803_nt37705_1240_2772_dsc_cmd {
		qcom,dsi-display-active;
	};
};

&dsi_oplus22803_nt37705_1240_2772_dsc_cmd {
	qcom,panel-supply-entries = <&dsi_panel_oplus_optimization_pwr_supply>;
	qcom,mdss-dsi-panel-controller = <&mdss_dsi0>;
	qcom,mdss-dsi-bl-pmic-control-type = "bl_ctrl_dcs";
	qcom,bl-update-flag = "delay_until_first_frame";
	qcom,mdss-dsi-bl-min-level = <1>;
	qcom,mdss-dsi-bl-max-level = <4095>;
	qcom,mdss-brightness-max-level = <4095>;
	oplus,dsi-bl-normal-max-level = <3515>;
	oplus,dsi-brightness-normal-max-level = <3515>;
	oplus,dsi-dc-backlight-threshold = <1960>;
	oplus,dsi-brightness-default-level = <1638>;
	qcom,platform-te-gpio = <&tlmm 86 0>;
	qcom,dynamic-te-gpio = <&tlmm 23 0>;
	qcom,platform-reset-gpio = <&tlmm 3 0>;
	qcom,platform-panel-vout-gpio = <&tlmm 90 0>;

	qcom,mdss-dsi-bl-inverted-dbv;
	qcom,ulps-enabled;
	qcom,dsi-select-clocks = "pll_byte_clk0", "pll_dsi_clk0";
	/* ofp config */
	oplus,ofp-fp-type = <0x08>;
	oplus,ofp-need-to-wait-data-before-aod-on;

	/* adfr config */
	/* just for qsync enable*/
	qcom,qsync-enable;
	qcom,mdss-dsi-qsync-min-refresh-rate = <24>;
	/*
	** 0st bit: adfr global on/off
	** 1st bit: fakeframe on/off
	** 2st bit: switch on/off
	** 3rd bit: 0:double-TE switch 1:external TE/TP switch
	** 4rd bit: idle mode on/off
	*/
	oplus,adfr-config = <9>;

	qcom,mdss-dsi-display-timings {
		timing@sdc_fhd_120 { /* FHD+ 120hz 550Mhz 1100Mbps */
			qcom,mdss-dsi-panel-phy-timings = [00 24 0A 0A 1A 24 0A 0A 09 02 04 00 1E 0F];
			qcom,display-topology = <1 1 1>,<2 2 1>;
			qcom,default-topology-index = <1>;
		};
		timing@sdc_fhd_90 { /* FHD+ 90hz 550Mhz 1100Mbps */
			qcom,mdss-dsi-panel-phy-timings = [00 24 0A 0A 1A 24 0A 0A 09 02 04 00 1E 0F];
			qcom,display-topology = <1 1 1>,<2 2 1>;
			qcom,default-topology-index = <1>;
		};
		timing@sdc_fhd_60 { /* FHD+ 60hz 550Mhz 1100Mbps */
			qcom,mdss-dsi-panel-phy-timings = [00 24 0A 0A 1A 24 0A 0A 09 02 04 00 1E 0F];
			qcom,display-topology = <1 1 1>,<2 2 1>;
			qcom,default-topology-index = <1>;
		};
		timing@oplus_fhd_120 { /* FHD+ 120hz 550Mhz 1100Mbps */
			qcom,mdss-dsi-panel-phy-timings = [00 24 0A 0A 1A 25 09 0A 09 02 04 00 1E 0F];
			qcom,display-topology = <1 1 1>,<2 2 1>;
			qcom,default-topology-index = <1>;
		};
	};
};
&dsi_oplus22803_nt37705_1240_2772_dsc_cmd {
	qcom,panel_voltage_vddi_name = "vddio";
	qcom,panel_voltage_vddi = <0 1800000 1850000 1950000>;
	qcom,panel_voltage_vddr_name = "vddio";
	qcom,panel_voltage_vddr = <1 1800000 1850000 1950000>;
};

&dsi_oplus22803_nt37705_1240_2772_dsc_cmd{
	oplus,color_vivid_status;
	oplus,color_srgb_status;
	oplus,color_softiris_status;
	oplus,color_dual_brightness_status;

	/* serial num config */
	oplus,dsi-serial-number-enabled;
	oplus,dsi-serial-number-switch-page;
	oplus,dsi-serial-number-index= <0>;
	oplus,dsi-serial-number-reg= <0xD7>;
	oplus,dsi-serial-number-read-count= <7>;
};

